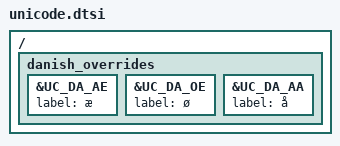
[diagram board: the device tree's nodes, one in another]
/ {
    danish_overrides {
        &UC_DA_AE {
            label = "æ";
        };
        &UC_DA_OE {
            label = "ø";
        };
        &UC_DA_AA {
            label = "å";
        };
    };
};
